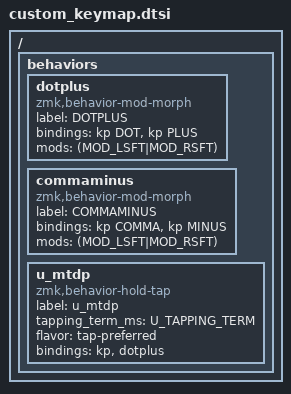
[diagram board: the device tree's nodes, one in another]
// Copyright 2022 Manna Harbour
// https://github.com/manna-harbour/miryoku

// added by Aubrey

/ {
  behaviors {
    dotplus: dotplus {
      compatible = "zmk,behavior-mod-morph";
      label = "DOTPLUS";
      #binding-cells = <0>;
      bindings = <&kp DOT>, <&kp PLUS>;
      mods = <(MOD_LSFT|MOD_RSFT)>;
    };
    commaminus: commaminus {
      compatible = "zmk,behavior-mod-morph";
      label = "COMMAMINUS";
      #binding-cells = <0>;
      bindings = <&kp COMMA>, <&kp MINUS>;
      mods = <(MOD_LSFT|MOD_RSFT)>;
    };
    u_mtdp: u_mtdp {
      compatible = "zmk,behavior-hold-tap";
      label = "u_mtdp";
      #binding-cells = <2>;
      tapping_term_ms = <U_TAPPING_TERM>;
      flavor = "tap-preferred";
      bindings = <&kp>, <&dotplus>;
    };
  };
};
